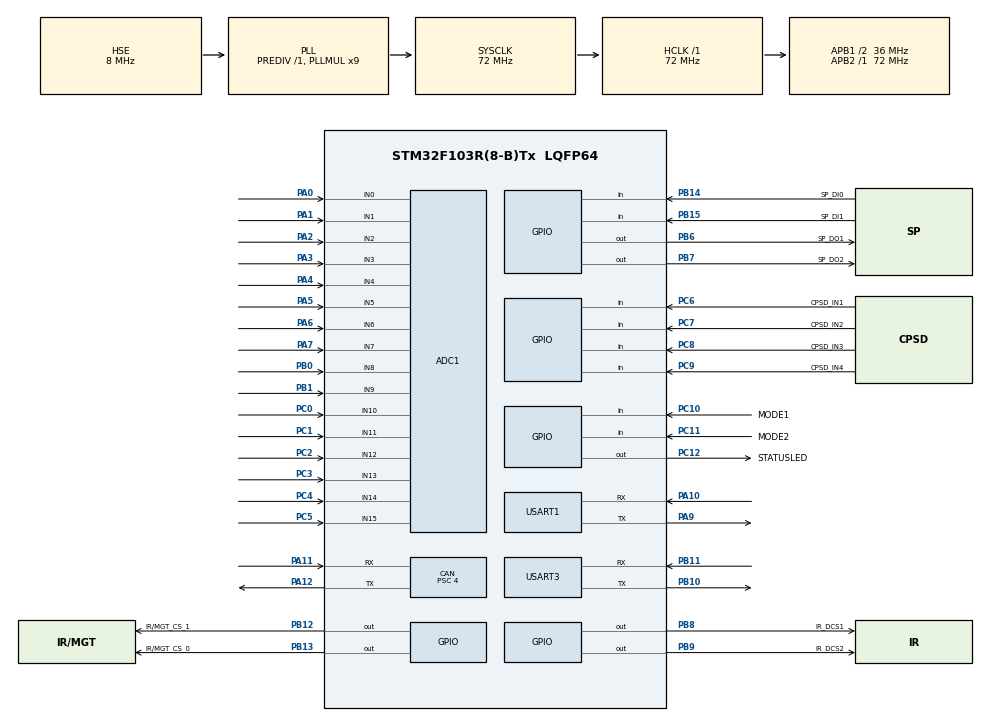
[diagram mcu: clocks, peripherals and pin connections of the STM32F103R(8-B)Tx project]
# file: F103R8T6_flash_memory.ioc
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ADC1.Channel-19\#ChannelRegularConversion=ADC_CHANNEL_1
ADC1.Channel-20\#ChannelRegularConversion=ADC_CHANNEL_2
ADC1.Channel-21\#ChannelRegularConversion=ADC_CHANNEL_3
ADC1.Channel-22\#ChannelRegularConversion=ADC_CHANNEL_4
ADC1.Channel-23\#ChannelRegularConversion=ADC_CHANNEL_5
ADC1.Channel-24\#ChannelRegularConversion=ADC_CHANNEL_6
ADC1.Channel-25\#ChannelRegularConversion=ADC_CHANNEL_7
ADC1.Channel-26\#ChannelRegularConversion=ADC_CHANNEL_8
ADC1.Channel-27\#ChannelRegularConversion=ADC_CHANNEL_9
ADC1.Channel-28\#ChannelRegularConversion=ADC_CHANNEL_10
ADC1.Channel-29\#ChannelRegularConversion=ADC_CHANNEL_11
ADC1.Channel-3\#ChannelRegularConversion=ADC_CHANNEL_0
ADC1.Channel-30\#ChannelRegularConversion=ADC_CHANNEL_12
ADC1.Channel-31\#ChannelRegularConversion=ADC_CHANNEL_13
ADC1.Channel-32\#ChannelRegularConversion=ADC_CHANNEL_14
ADC1.Channel-33\#ChannelRegularConversion=ADC_CHANNEL_15
ADC1.ContinuousConvMode=DISABLE
ADC1.DiscontinuousConvMode=DISABLE
ADC1.EnableAnalogWatchDog=false
ADC1.EnableInjectedConversion=DISABLE
ADC1.ExternalTrigConv=ADC_SOFTWARE_START
ADC1.NbrOfConversion=16
ADC1.NbrOfConversionFlag=1
ADC1.Rank-19\#ChannelRegularConversion=2
ADC1.Rank-20\#ChannelRegularConversion=3
ADC1.Rank-21\#ChannelRegularConversion=4
ADC1.Rank-22\#ChannelRegularConversion=5
ADC1.Rank-23\#ChannelRegularConversion=6
ADC1.Rank-24\#ChannelRegularConversion=7
ADC1.Rank-25\#ChannelRegularConversion=8
ADC1.Rank-26\#ChannelRegularConversion=9
ADC1.Rank-27\#ChannelRegularConversion=10
ADC1.Rank-28\#ChannelRegularConversion=11
ADC1.Rank-29\#ChannelRegularConversion=12
ADC1.Rank-3\#ChannelRegularConversion=1
ADC1.Rank-30\#ChannelRegularConversion=13
ADC1.Rank-31\#ChannelRegularConversion=14
ADC1.Rank-32\#ChannelRegularConversion=15
ADC1.Rank-33\#ChannelRegularConversion=16
ADC1.SamplingTime-19\#ChannelRegularConversion=ADC_SAMPLETIME_1CYCLE_5
ADC1.SamplingTime-20\#ChannelRegularConversion=ADC_SAMPLETIME_1CYCLE_5
ADC1.SamplingTime-21\#ChannelRegularConversion=ADC_SAMPLETIME_1CYCLE_5
ADC1.SamplingTime-22\#ChannelRegularConversion=ADC_SAMPLETIME_1CYCLE_5
ADC1.SamplingTime-23\#ChannelRegularConversion=ADC_SAMPLETIME_1CYCLE_5
ADC1.SamplingTime-24\#ChannelRegularConversion=ADC_SAMPLETIME_1CYCLE_5
ADC1.SamplingTime-25\#ChannelRegularConversion=ADC_SAMPLETIME_1CYCLE_5
ADC1.SamplingTime-26\#ChannelRegularConversion=ADC_SAMPLETIME_1CYCLE_5
ADC1.SamplingTime-27\#ChannelRegularConversion=ADC_SAMPLETIME_1CYCLE_5
ADC1.SamplingTime-28\#ChannelRegularConversion=ADC_SAMPLETIME_1CYCLE_5
ADC1.SamplingTime-29\#ChannelRegularConversion=ADC_SAMPLETIME_1CYCLE_5
ADC1.SamplingTime-3\#ChannelRegularConversion=ADC_SAMPLETIME_1CYCLE_5
ADC1.SamplingTime-30\#ChannelRegularConversion=ADC_SAMPLETIME_1CYCLE_5
ADC1.SamplingTime-31\#ChannelRegularConversion=ADC_SAMPLETIME_1CYCLE_5
ADC1.SamplingTime-32\#ChannelRegularConversion=ADC_SAMPLETIME_1CYCLE_5
ADC1.SamplingTime-33\#ChannelRegularConversion=ADC_SAMPLETIME_1CYCLE_5
ADC1.master=1
CAN.BS1=CAN_BS1_15TQ
CAN.BS2=CAN_BS2_2TQ
CAN.CalculateBaudRate=500000
CAN.CalculateTimeBit=2000
CAN.CalculateTimeQuantum=111.11111111111111
CAN.Mode=CAN_MODE_NORMAL
CAN.NART=ENABLE
CAN.Prescaler=4
Dma.ADC1.0.Direction=DMA_PERIPH_TO_MEMORY
Dma.ADC1.0.Instance=DMA1_Channel1
Dma.ADC1.0.MemDataAlignment=DMA_MDATAALIGN_HALFWORD
Dma.ADC1.0.MemInc=DMA_MINC_ENABLE
Dma.ADC1.0.Mode=DMA_CIRCULAR
Dma.ADC1.0.PeriphDataAlignment=DMA_PDATAALIGN_HALFWORD
Dma.ADC1.0.PeriphInc=DMA_PINC_DISABLE
Dma.ADC1.0.Priority=DMA_PRIORITY_LOW
Dma.Request0=ADC1
Mcu.Family=STM32F1
Mcu.Name=STM32F103R(8-B)Tx
Mcu.Package=LQFP64
NVIC.ADC1_2_IRQn=true\:0\:0\:false\:false\:true\:true\:true\:true
NVIC.CAN1_RX1_IRQn=true\:0\:0\:false\:false\:true\:true\:true\:true
NVIC.CAN1_SCE_IRQn=true\:0\:0\:false\:false\:true\:true\:true\:true
NVIC.DMA1_Channel1_IRQn=true\:0\:0\:false\:false\:true\:false\:true\:true
NVIC.PriorityGroup=NVIC_PRIORITYGROUP_4
NVIC.TIM1_UP_IRQn=true\:0\:0\:false\:false\:true\:true\:true\:true
NVIC.USART1_IRQn=true\:0\:0\:false\:false\:true\:true\:true\:true
NVIC.USART3_IRQn=true\:0\:0\:false\:false\:true\:true\:true\:true
NVIC.USB_HP_CAN1_TX_IRQn=true\:0\:0\:false\:false\:true\:true\:true\:true
NVIC.USB_LP_CAN1_RX0_IRQn=true\:0\:0\:false\:false\:true\:true\:true\:true
PA0-WKUP.Signal=ADCx_IN0
PA1.Signal=ADCx_IN1
PA10.Mode=Asynchronous
PA10.Signal=USART1_RX
PA11.Mode=CAN_Activate
PA11.Signal=CAN_RX
PA12.Mode=CAN_Activate
PA12.Signal=CAN_TX
PA13.Mode=JTAG_5_pins
PA13.Signal=SYS_JTMS-SWDIO
PA14.Mode=JTAG_5_pins
PA14.Signal=SYS_JTCK-SWCLK
PA15.Mode=JTAG_5_pins
PA15.Signal=SYS_JTDI
PA2.Signal=ADCx_IN2
PA3.Signal=ADCx_IN3
PA4.Signal=ADCx_IN4
PA5.Signal=ADCx_IN5
PA6.Signal=ADCx_IN6
PA7.Signal=ADCx_IN7
PA9.Mode=Asynchronous
PA9.Signal=USART1_TX
PB0.Signal=ADCx_IN8
PB1.Signal=ADCx_IN9
PB10.Mode=Asynchronous
PB10.Signal=USART3_TX
PB11.Mode=Asynchronous
PB11.Signal=USART3_RX
PB12.GPIO_Label=IR/MGT_CS_1
PB12.Signal=GPIO_Output
PB13.GPIO_Label=IR/MGT_CS_0
PB13.Signal=GPIO_Output
PB14.GPIO_Label=SP_DI0
PB14.Signal=GPIO_Input
PB15.GPIO_Label=SP_DI1
PB15.Signal=GPIO_Input
PB3.Mode=JTAG_5_pins
PB3.Signal=SYS_JTDO-TRACESWO
PB4.Mode=JTAG_5_pins
PB4.Signal=SYS_NJTRST
PB6.GPIO_Label=SP_DO1
PB6.Signal=GPIO_Output
PB7.GPIO_Label=SP_DO2
PB7.Signal=GPIO_Output
PB8.GPIO_Label=IR_DCS1
PB8.Signal=GPIO_Output
PB9.GPIO_Label=IR_DCS2
PB9.Signal=GPIO_Output
PC0.Signal=ADCx_IN10
PC1.Signal=ADCx_IN11
PC10.GPIO_Label=MODE1
PC10.Signal=GPIO_Input
PC11.GPIO_Label=MODE2
PC11.Signal=GPIO_Input
PC12.GPIO_Label=STATUSLED
PC12.Signal=GPIO_Output
PC2.Signal=ADCx_IN12
PC3.Signal=ADCx_IN13
PC4.Signal=ADCx_IN14
PC5.Signal=ADCx_IN15
PC6.GPIO_Label=CPSD_IN1
PC6.Signal=GPIO_Input
PC7.GPIO_Label=CPSD_IN2
PC7.Signal=GPIO_Input
PC8.GPIO_Label=CPSD_IN3
PC8.Signal=GPIO_Input
PC9.GPIO_Label=CPSD_IN4
PC9.Signal=GPIO_Input
PD0-OSC_IN.Mode=HSE-External-Oscillator
PD0-OSC_IN.Signal=RCC_OSC_IN
PD1-OSC_OUT.Mode=HSE-External-Oscillator
PD1-OSC_OUT.Signal=RCC_OSC_OUT
ProjectManager.HeapSize=0x200
ProjectManager.StackSize=0x400
ProjectManager.TargetToolchain=STM32CubeIDE
RCC.ADCPresc=RCC_ADCPCLK2_DIV6
RCC.AHBFreq_Value=72000000
RCC.APB1CLKDivider=RCC_HCLK_DIV2
RCC.APB1Freq_Value=36000000
RCC.APB1TimFreq_Value=72000000
RCC.APB2Freq_Value=72000000
RCC.APB2TimFreq_Value=72000000
RCC.HCLKFreq_Value=72000000
RCC.PLLMUL=RCC_PLL_MUL9
RCC.PLLSourceVirtual=RCC_PLLSOURCE_HSE
RCC.SYSCLKFreq_VALUE=72000000
RCC.SYSCLKSource=RCC_SYSCLKSOURCE_PLLCLK
RCC.USBFreq_Value=72000000
SH.ADCx_IN0.0=ADC1_IN0,IN0
SH.ADCx_IN1.0=ADC1_IN1,IN1
SH.ADCx_IN10.0=ADC1_IN10,IN10
SH.ADCx_IN11.0=ADC1_IN11,IN11
SH.ADCx_IN12.0=ADC1_IN12,IN12
SH.ADCx_IN13.0=ADC1_IN13,IN13
SH.ADCx_IN14.0=ADC1_IN14,IN14
SH.ADCx_IN15.0=ADC1_IN15,IN15
SH.ADCx_IN2.0=ADC1_IN2,IN2
SH.ADCx_IN3.0=ADC1_IN3,IN3
SH.ADCx_IN4.0=ADC1_IN4,IN4
SH.ADCx_IN5.0=ADC1_IN5,IN5
SH.ADCx_IN6.0=ADC1_IN6,IN6
SH.ADCx_IN7.0=ADC1_IN7,IN7
SH.ADCx_IN8.0=ADC1_IN8,IN8
SH.ADCx_IN9.0=ADC1_IN9,IN9
TIM1.Period=1000
TIM1.Prescaler=72 - 1
USART1.VirtualMode=VM_ASYNC
USART3.VirtualMode=VM_ASYNC
VP_TIM1_VS_ClockSourceINT.Mode=Internal
board=custom

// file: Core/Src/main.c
/* USER CODE BEGIN Header */
/**
  ******************************************************************************
  * @file           : main.c
  * @brief          : Main program body
  ******************************************************************************
  * @attention
  *
  * Copyright (c) 2024 STMicroelectronics.
  * All rights reserved.
  *
  * This software is licensed under terms that can be found in the LICENSE file
  * in the root directory of this software component.
  * If no LICENSE file comes with this software, it is provided AS-IS.
  *
  ******************************************************************************
  */
/* USER CODE END Header */
#include "main.h"

/* USER CODE BEGIN Includes */
#include <stdio.h>
/* USER CODE END Includes */

ADC_HandleTypeDef hadc1;
DMA_HandleTypeDef hdma_adc1;

CAN_HandleTypeDef hcan;

TIM_HandleTypeDef htim1;

UART_HandleTypeDef huart1;
UART_HandleTypeDef huart3;

void SystemClock_Config(void);
static void MX_GPIO_Init(void);
static void MX_DMA_Init(void);
static void MX_ADC1_Init(void);
static void MX_CAN_Init(void);
static void MX_USART1_UART_Init(void);
static void MX_USART3_UART_Init(void);
static void MX_TIM1_Init(void);

int main(void)
{

  /* MCU Configuration--------------------------------------------------------*/

  /* Reset of all peripherals, Initializes the Flash interface and the Systick. */
  HAL_Init();

  /* Configure the system clock */
  SystemClock_Config();

  /* Initialize all configured peripherals */
  MX_GPIO_Init();
  MX_DMA_Init();
  MX_ADC1_Init();
  MX_CAN_Init();
  MX_USART1_UART_Init();
  MX_USART3_UART_Init();
  MX_TIM1_Init();
  /* USER CODE BEGIN 2 */
  uint32_t PAGEError = 0;
  static FLASH_EraseInitTypeDef EraseInitStruct;
  // flash memory nulock
  HAL_FLASH_Unlock();

  EraseInitStruct.TypeErase = FLASH_TYPEERASE_PAGES;
	EraseInitStruct.PageAddress = START_ADDR;
	EraseInitStruct.NbPages = (END_ADDR - START_ADDR) / 1024;
	HAL_FLASHEx_Erase(&EraseInitStruct, &PAGEError);

	// write
	HAL_FLASH_Program(FLASH_TYPEPROGRAM_WORD, FLASH_USER + 0, 0x12345678);
	HAL_FLASH_Program(FLASH_TYPEPROGRAM_WORD, FLASH_USER + 4, 0x22345678);
	HAL_FLASH_Program(FLASH_TYPEPROGRAM_WORD, FLASH_USER + 8, 0x32345678);
	HAL_FLASH_Program(FLASH_TYPEPROGRAM_WORD, FLASH_USER + 12, 0x42345678);

	HAL_FLASH_Lock();

	// read
	uint32_t viewer = *(uint32_t*)FLASH_USER;

  /* USER CODE END 2 */

  /* Infinite loop */
  while (1)
  {

  }
}

void SystemClock_Config(void)
{
  RCC_OscInitTypeDef RCC_OscInitStruct = {0};
  RCC_ClkInitTypeDef RCC_ClkInitStruct = {0};
  RCC_PeriphCLKInitTypeDef PeriphClkInit = {0};

  /** Initializes the RCC Oscillators according to the specified parameters
  * in the RCC_OscInitTypeDef structure.
  */
  RCC_OscInitStruct.OscillatorType = RCC_OSCILLATORTYPE_HSE;
  RCC_OscInitStruct.HSEState = RCC_HSE_ON;
  RCC_OscInitStruct.HSEPredivValue = RCC_HSE_PREDIV_DIV1;
  RCC_OscInitStruct.HSIState = RCC_HSI_ON;
  RCC_OscInitStruct.PLL.PLLState = RCC_PLL_ON;
  RCC_OscInitStruct.PLL.PLLSource = RCC_PLLSOURCE_HSE;
  RCC_OscInitStruct.PLL.PLLMUL = RCC_PLL_MUL9;
  if (HAL_RCC_OscConfig(&RCC_OscInitStruct) != HAL_OK)
  {
    Error_Handler();
  }

  /** Initializes the CPU, AHB and APB buses clocks
  */
  RCC_ClkInitStruct.ClockType = RCC_CLOCKTYPE_HCLK|RCC_CLOCKTYPE_SYSCLK
                              |RCC_CLOCKTYPE_PCLK1|RCC_CLOCKTYPE_PCLK2;
  RCC_ClkInitStruct.SYSCLKSource = RCC_SYSCLKSOURCE_PLLCLK;
  RCC_ClkInitStruct.AHBCLKDivider = RCC_SYSCLK_DIV1;
  RCC_ClkInitStruct.APB1CLKDivider = RCC_HCLK_DIV2;
  RCC_ClkInitStruct.APB2CLKDivider = RCC_HCLK_DIV1;

  if (HAL_RCC_ClockConfig(&RCC_ClkInitStruct, FLASH_LATENCY_2) != HAL_OK)
  {
    Error_Handler();
  }
  PeriphClkInit.PeriphClockSelection = RCC_PERIPHCLK_ADC;
  PeriphClkInit.AdcClockSelection = RCC_ADCPCLK2_DIV6;
  if (HAL_RCCEx_PeriphCLKConfig(&PeriphClkInit) != HAL_OK)
  {
    Error_Handler();
  }
}

static void MX_ADC1_Init(void)
{

  ADC_ChannelConfTypeDef sConfig = {0};

  /** Common config
  */
  hadc1.Instance = ADC1;
  hadc1.Init.ScanConvMode = ADC_SCAN_ENABLE;
  hadc1.Init.ContinuousConvMode = DISABLE;
  hadc1.Init.DiscontinuousConvMode = DISABLE;
  hadc1.Init.ExternalTrigConv = ADC_SOFTWARE_START;
  hadc1.Init.DataAlign = ADC_DATAALIGN_RIGHT;
  hadc1.Init.NbrOfConversion = 16;
  if (HAL_ADC_Init(&hadc1) != HAL_OK)
  {
    Error_Handler();
  }

  /** Configure Regular Channel
  */
  sConfig.Channel = ADC_CHANNEL_0;
  sConfig.Rank = ADC_REGULAR_RANK_1;
  sConfig.SamplingTime = ADC_SAMPLETIME_1CYCLE_5;
  if (HAL_ADC_ConfigChannel(&hadc1, &sConfig) != HAL_OK)
  {
    Error_Handler();
  }

  /** Configure Regular Channel
  */
  sConfig.Channel = ADC_CHANNEL_1;
  sConfig.Rank = ADC_REGULAR_RANK_2;
  if (HAL_ADC_ConfigChannel(&hadc1, &sConfig) != HAL_OK)
  {
    Error_Handler();
  }

  /** Configure Regular Channel
  */
  sConfig.Channel = ADC_CHANNEL_2;
  sConfig.Rank = ADC_REGULAR_RANK_3;
  if (HAL_ADC_ConfigChannel(&hadc1, &sConfig) != HAL_OK)
  {
    Error_Handler();
  }

  /** Configure Regular Channel
  */
  sConfig.Channel = ADC_CHANNEL_3;
  sConfig.Rank = ADC_REGULAR_RANK_4;
  if (HAL_ADC_ConfigChannel(&hadc1, &sConfig) != HAL_OK)
  {
    Error_Handler();
  }

  /** Configure Regular Channel
  */
  sConfig.Channel = ADC_CHANNEL_4;
  sConfig.Rank = ADC_REGULAR_RANK_5;
  if (HAL_ADC_ConfigChannel(&hadc1, &sConfig) != HAL_OK)
  {
    Error_Handler();
  }

  /** Configure Regular Channel
  */
  sConfig.Channel = ADC_CHANNEL_5;
  sConfig.Rank = ADC_REGULAR_RANK_6;
  if (HAL_ADC_ConfigChannel(&hadc1, &sConfig) != HAL_OK)
  {
    Error_Handler();
  }

  /** Configure Regular Channel
  */
  sConfig.Channel = ADC_CHANNEL_6;
  sConfig.Rank = ADC_REGULAR_RANK_7;
  if (HAL_ADC_ConfigChannel(&hadc1, &sConfig) != HAL_OK)
  {
    Error_Handler();
  }

  /** Configure Regular Channel
  */
  sConfig.Channel = ADC_CHANNEL_7;
  sConfig.Rank = ADC_REGULAR_RANK_8;
  if (HAL_ADC_ConfigChannel(&hadc1, &sConfig) != HAL_OK)
  {
    Error_Handler();
  }

  /** Configure Regular Channel
  */
  sConfig.Channel = ADC_CHANNEL_8;
  sConfig.Rank = ADC_REGULAR_RANK_9;
  if (HAL_ADC_ConfigChannel(&hadc1, &sConfig) != HAL_OK)
  {
    Error_Handler();
  }

  /** Configure Regular Channel
  */
  sConfig.Channel = ADC_CHANNEL_9;
  sConfig.Rank = ADC_REGULAR_RANK_10;
  if (HAL_ADC_ConfigChannel(&hadc1, &sConfig) != HAL_OK)
  {
    Error_Handler();
  }

  /** Configure Regular Channel
  */
  sConfig.Channel = ADC_CHANNEL_10;
  sConfig.Rank = ADC_REGULAR_RANK_11;
  if (HAL_ADC_ConfigChannel(&hadc1, &sConfig) != HAL_OK)
  {
    Error_Handler();
  }

  /** Configure Regular Channel
  */
  sConfig.Channel = ADC_CHANNEL_11;
  sConfig.Rank = ADC_REGULAR_RANK_12;
  if (HAL_ADC_ConfigChannel(&hadc1, &sConfig) != HAL_OK)
  {
    Error_Handler();
  }

  /** Configure Regular Channel
  */
  sConfig.Channel = ADC_CHANNEL_12;
  sConfig.Rank = ADC_REGULAR_RANK_13;
  if (HAL_ADC_ConfigChannel(&hadc1, &sConfig) != HAL_OK)
  {
    Error_Handler();
  }

  /** Configure Regular Channel
  */
  sConfig.Channel = ADC_CHANNEL_13;
  sConfig.Rank = ADC_REGULAR_RANK_14;
  if (HAL_ADC_ConfigChannel(&hadc1, &sConfig) != HAL_OK)
  {
    Error_Handler();
  }

  /** Configure Regular Channel
  */
  sConfig.Channel = ADC_CHANNEL_14;
  sConfig.Rank = ADC_REGULAR_RANK_15;
  if (HAL_ADC_ConfigChannel(&hadc1, &sConfig) != HAL_OK)
  {
    Error_Handler();
  }

  /** Configure Regular Channel
  */
  sConfig.Channel = ADC_CHANNEL_15;
  sConfig.Rank = ADC_REGULAR_RANK_16;
  if (HAL_ADC_ConfigChannel(&hadc1, &sConfig) != HAL_OK)
  {
    Error_Handler();
  }

}

static void MX_CAN_Init(void)
{

  hcan.Instance = CAN1;
  hcan.Init.Prescaler = 4;
  hcan.Init.Mode = CAN_MODE_NORMAL;
  hcan.Init.SyncJumpWidth = CAN_SJW_1TQ;
  hcan.Init.TimeSeg1 = CAN_BS1_15TQ;
  hcan.Init.TimeSeg2 = CAN_BS2_2TQ;
  hcan.Init.TimeTriggeredMode = DISABLE;
  hcan.Init.AutoBusOff = DISABLE;
  hcan.Init.AutoWakeUp = DISABLE;
  hcan.Init.AutoRetransmission = ENABLE;
  hcan.Init.ReceiveFifoLocked = DISABLE;
  hcan.Init.TransmitFifoPriority = DISABLE;
  if (HAL_CAN_Init(&hcan) != HAL_OK)
  {
    Error_Handler();
  }

}

static void MX_TIM1_Init(void)
{

  TIM_ClockConfigTypeDef sClockSourceConfig = {0};
  TIM_MasterConfigTypeDef sMasterConfig = {0};

  htim1.Instance = TIM1;
  htim1.Init.Prescaler = 72 - 1;
  htim1.Init.CounterMode = TIM_COUNTERMODE_UP;
  htim1.Init.Period = 1000;
  htim1.Init.ClockDivision = TIM_CLOCKDIVISION_DIV1;
  htim1.Init.RepetitionCounter = 0;
  htim1.Init.AutoReloadPreload = TIM_AUTORELOAD_PRELOAD_DISABLE;
  if (HAL_TIM_Base_Init(&htim1) != HAL_OK)
  {
    Error_Handler();
  }
  sClockSourceConfig.ClockSource = TIM_CLOCKSOURCE_INTERNAL;
  if (HAL_TIM_ConfigClockSource(&htim1, &sClockSourceConfig) != HAL_OK)
  {
    Error_Handler();
  }
  sMasterConfig.MasterOutputTrigger = TIM_TRGO_RESET;
  sMasterConfig.MasterSlaveMode = TIM_MASTERSLAVEMODE_DISABLE;
  if (HAL_TIMEx_MasterConfigSynchronization(&htim1, &sMasterConfig) != HAL_OK)
  {
    Error_Handler();
  }

}

static void MX_USART1_UART_Init(void)
{

  huart1.Instance = USART1;
  huart1.Init.BaudRate = 115200;
  huart1.Init.WordLength = UART_WORDLENGTH_8B;
  huart1.Init.StopBits = UART_STOPBITS_1;
  huart1.Init.Parity = UART_PARITY_NONE;
  huart1.Init.Mode = UART_MODE_TX_RX;
  huart1.Init.HwFlowCtl = UART_HWCONTROL_NONE;
  huart1.Init.OverSampling = UART_OVERSAMPLING_16;
  if (HAL_UART_Init(&huart1) != HAL_OK)
  {
    Error_Handler();
  }

}

static void MX_USART3_UART_Init(void)
{

  huart3.Instance = USART3;
  huart3.Init.BaudRate = 115200;
  huart3.Init.WordLength = UART_WORDLENGTH_8B;
  huart3.Init.StopBits = UART_STOPBITS_1;
  huart3.Init.Parity = UART_PARITY_NONE;
  huart3.Init.Mode = UART_MODE_TX_RX;
  huart3.Init.HwFlowCtl = UART_HWCONTROL_NONE;
  huart3.Init.OverSampling = UART_OVERSAMPLING_16;
  if (HAL_UART_Init(&huart3) != HAL_OK)
  {
    Error_Handler();
  }

}

static void MX_DMA_Init(void)
{

  /* DMA controller clock enable */
  __HAL_RCC_DMA1_CLK_ENABLE();

  /* DMA interrupt init */
  /* DMA1_Channel1_IRQn interrupt configuration */
  HAL_NVIC_SetPriority(DMA1_Channel1_IRQn, 0, 0);
  HAL_NVIC_EnableIRQ(DMA1_Channel1_IRQn);

}

static void MX_GPIO_Init(void)
{
  GPIO_InitTypeDef GPIO_InitStruct = {0};

  /* GPIO Ports Clock Enable */
  __HAL_RCC_GPIOD_CLK_ENABLE();
  __HAL_RCC_GPIOC_CLK_ENABLE();
  __HAL_RCC_GPIOA_CLK_ENABLE();
  __HAL_RCC_GPIOB_CLK_ENABLE();

  /*Configure GPIO pin Output Level */
  HAL_GPIO_WritePin(GPIOB, IR_MGT_CS_1_Pin|IR_MGT_CS_0_Pin|SP_DO1_Pin|SP_DO2_Pin
                          |IR_DCS1_Pin|IR_DCS2_Pin, GPIO_PIN_RESET);

  /*Configure GPIO pin Output Level */
  HAL_GPIO_WritePin(STATUSLED_GPIO_Port, STATUSLED_Pin, GPIO_PIN_RESET);

  /*Configure GPIO pins : IR_MGT_CS_1_Pin IR_MGT_CS_0_Pin SP_DO1_Pin SP_DO2_Pin
                           IR_DCS1_Pin IR_DCS2_Pin */
  GPIO_InitStruct.Pin = IR_MGT_CS_1_Pin|IR_MGT_CS_0_Pin|SP_DO1_Pin|SP_DO2_Pin
                          |IR_DCS1_Pin|IR_DCS2_Pin;
  GPIO_InitStruct.Mode = GPIO_MODE_OUTPUT_PP;
  GPIO_InitStruct.Pull = GPIO_NOPULL;
  GPIO_InitStruct.Speed = GPIO_SPEED_FREQ_LOW;
  HAL_GPIO_Init(GPIOB, &GPIO_InitStruct);

  /*Configure GPIO pins : SP_DI0_Pin SP_DI1_Pin */
  GPIO_InitStruct.Pin = SP_DI0_Pin|SP_DI1_Pin;
  GPIO_InitStruct.Mode = GPIO_MODE_INPUT;
  GPIO_InitStruct.Pull = GPIO_NOPULL;
  HAL_GPIO_Init(GPIOB, &GPIO_InitStruct);

  /*Configure GPIO pins : CPSD_IN1_Pin CPSD_IN2_Pin CPSD_IN3_Pin CPSD_IN4_Pin
                           MODE1_Pin MODE2_Pin */
  GPIO_InitStruct.Pin = CPSD_IN1_Pin|CPSD_IN2_Pin|CPSD_IN3_Pin|CPSD_IN4_Pin
                          |MODE1_Pin|MODE2_Pin;
  GPIO_InitStruct.Mode = GPIO_MODE_INPUT;
  GPIO_InitStruct.Pull = GPIO_NOPULL;
  HAL_GPIO_Init(GPIOC, &GPIO_InitStruct);

  /*Configure GPIO pin : STATUSLED_Pin */
  GPIO_InitStruct.Pin = STATUSLED_Pin;
  GPIO_InitStruct.Mode = GPIO_MODE_OUTPUT_PP;
  GPIO_InitStruct.Pull = GPIO_NOPULL;
  GPIO_InitStruct.Speed = GPIO_SPEED_FREQ_LOW;
  HAL_GPIO_Init(STATUSLED_GPIO_Port, &GPIO_InitStruct);

}

void Error_Handler(void)
{
  __disable_irq();
  while (1)
  {
  }
}
